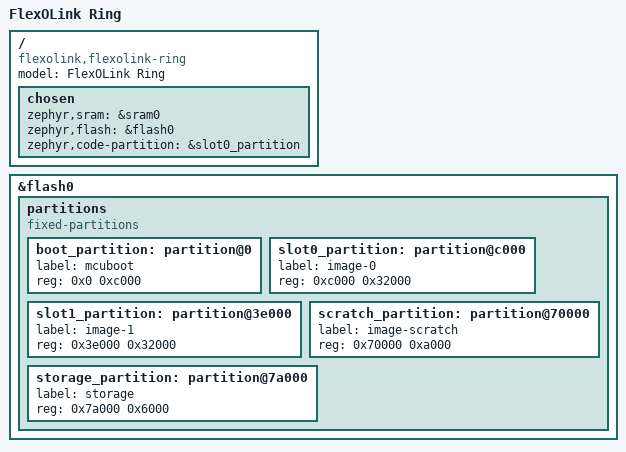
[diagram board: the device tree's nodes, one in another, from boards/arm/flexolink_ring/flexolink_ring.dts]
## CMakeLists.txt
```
list(APPEND ZEPHYR_EXTRA_MODULES
  ${CMAKE_CURRENT_SOURCE_DIR}/icm20948
  ${CMAKE_CURRENT_SOURCE_DIR}/ad4696
  ${CMAKE_CURRENT_SOURCE_DIR}/ble
)

cmake_minimum_required(VERSION 3.13.1)
find_package(Zephyr REQUIRED HINTS $ENV{ZEPHYR_BASE})
project(blinky)

target_sources(app PRIVATE 
    src/main.c
)
```

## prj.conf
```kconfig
CONFIG_AD4696_DRIVER=y
CONFIG_ICM20948_DRIVER=y
CONFIG_BLE_SERVICE=y
CONFIG_APPLICATION_DEFINED_SYSCALL=y

# CONFIG_GPIO=y

# SPI
CONFIG_DEBUG_OPTIMIZATIONS=y
CONFIG_COMPILER_OPT=""
CONFIG_SPI=y

CONFIG_BT=y
CONFIG_BT_PERIPHERAL=y
CONFIG_BT_USER_DATA_LEN_UPDATE=y
CONFIG_BT_DEVICE_NAME="FlexOLink-Ring"

CONFIG_BT_BUF_ACL_RX_SIZE=251
CONFIG_BT_BUF_ACL_TX_COUNT=2
CONFIG_BT_BUF_ACL_TX_SIZE=251
CONFIG_BT_CTLR_DATA_LENGTH_MAX=251
CONFIG_BT_L2CAP_TX_MTU=247
CONFIG_BT_GATT_CLIENT=y

CONFIG_USE_SEGGER_RTT=y
CONFIG_RTT_CONSOLE=y
CONFIG_UART_CONSOLE=n

CONFIG_LOG=y
CONFIG_LOG_PRINTK=y

# CONFIG_MAIN_STACK_SIZE=4096
```

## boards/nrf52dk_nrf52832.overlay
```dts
&spi1 {
	compatible = "nordic,nrf-spi";
	status = "okay";

	cs-gpios = <&gpio0 30 GPIO_ACTIVE_LOW>;
	sck-pin = <26>;
	mosi-pin = <28>;
	miso-pin = <31>;
};

&spi0 {
	compatible = "nordic,nrf-spi";
	status = "okay";
	
	cs-gpios = <&gpio0 21 GPIO_ACTIVE_LOW>;
	// sck-pin = <2>;
	// mosi-pin = <4>;
	// miso-pin = <0>;
};
```

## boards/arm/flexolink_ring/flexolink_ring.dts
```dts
// Copyright (c) 2021 Nordic Semiconductor ASA
// SPDX-License-Identifier: Apache-2.0

/dts-v1/;
#include <nordic/nrf52832_qfaa.dtsi>

/ {
	model = "FlexOLink Ring";
	compatible = "flexolink,flexolink-ring";

	chosen {
		zephyr,sram = &sram0;
		zephyr,flash = &flash0;
		zephyr,code-partition = &slot0_partition;
	};
};

&flash0 {
	partitions {
		compatible = "fixed-partitions";
		#address-cells = <1>;
		#size-cells = <1>;

		boot_partition: partition@0 {
			label = "mcuboot";
			reg = <0x0 0xc000>;
		};
		slot0_partition: partition@c000 {
			label = "image-0";
			reg = <0xc000 0x32000>;
		};
		slot1_partition: partition@3e000 {
			label = "image-1";
			reg = <0x3e000 0x32000>;
		};
		scratch_partition: partition@70000 {
			label = "image-scratch";
			reg = <0x70000 0xa000>;
		};
		storage_partition: partition@7a000 {
			label = "storage";
			reg = <0x7a000 0x6000>;
		};
	};
};
```

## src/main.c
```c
/*
 * Copyright (c) 2016 Intel Corporation
 *
 * SPDX-License-Identifier: Apache-2.0
 */

#include <zephyr.h>
#include <device.h>
#include <devicetree.h>
#include <drivers/gpio.h>
#include <logging/log.h>
#include <drivers/sensor.h>

#include "ad4696.h"
#include "icm20948.h"
#include "ble_service.h"

LOG_MODULE_REGISTER(main);

/* 1000 msec = 1 sec */
#define SLEEP_TIME_MS   1000

const struct device *dev, *ble_dev;
struct sensor_value ad4696_data[17];

static void user_entry(void *p1, void *p2, void *p3)
{
	ad4696_print(dev);
	k_msleep(5000);

	ad4696_setup(dev);
	
	while (true)
	{
		k_msleep(2000);
		
		ad4696_fetch_data(dev, ad4696_data);

		// LOG_INF("AD4696 data: ");
		// for (size_t i = 0; i < 17; i++)
		// {
		// 	printk("[%d]%d ", i, (int16_t)(sensor_value_to_double( &ad4696_data[i] ) * 1000000) ); // volt(µV)
		// }
		// printk("\n");

		if(ble_ready) {

			uint8_t data[] = {
				0x00, 0x01, 0x02, 0x03, 0x04, 0x05, 0x06, 0x07, 0x08, 0x09, 
				0x10, 0x01, 0x02, 0x03, 0x04, 0x05, 0x06, 0x07, 0x08, 0x09, 
				0x11, 0x01, 0x02, 0x03, 0x04, 0x05, 0x06, 0x07, 0x08, 0x09, 
			};

			ble_service_send(ble_dev, data, sizeof(data));
		}
	}
}


void main(void)
{
	LOG_INF("Hello World from the app!\n");

	// LOG_INF("SPI config begin ...");
	// icm20948_setup();
	// LOG_INF("Blinky with SPI started");

	// while (1) {
	// 	// printk("print in while loop\n");
	// 	icm20948_fetch_data();
	// 	k_msleep(1000);
	// }

	ble_dev = device_get_binding("BLE_SERVICE");
	ble_service_print(ble_dev);


	dev = device_get_binding("ADI_AD4696");

	__ASSERT(dev, "Failed to get device binding");
	LOG_INF("device is %p, name is %s", dev, dev->name);

	k_object_access_grant(dev, k_current_get());
	k_thread_user_mode_enter(user_entry, NULL, NULL, NULL);
}
```
